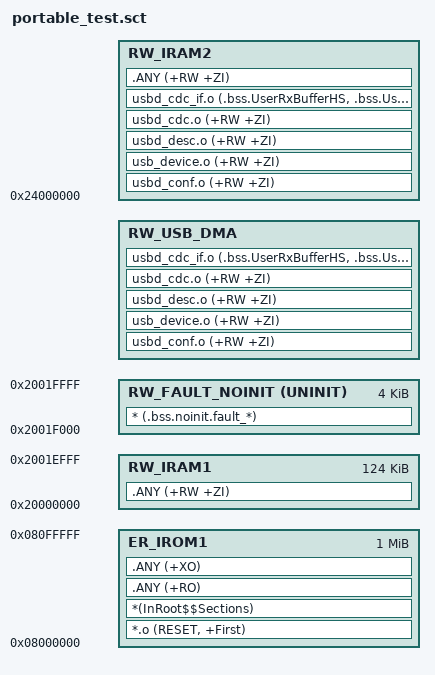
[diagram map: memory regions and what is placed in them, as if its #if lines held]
#! armclang -E --target=arm-arm-none-eabi -mcpu=cortex-m7 -xc
#include "D:/RM/recorder233/recorder_f405/diagnostics/user_add_readme/fixtures/USB portable project/User/Log/fault_log_config.h"
#include "D:/RM/recorder233/recorder_f405/diagnostics/user_add_readme/fixtures/USB portable project/User/Support/usb_dma_memory.h"
/* 故障保留区与缓存开关无关，始终保留。 */
LR_IROM1 0x08000000 0x00100000 {
  ER_IROM1 0x08000000 0x00100000 {
    *.o (RESET, +First)
    *(InRoot$$Sections)
    .ANY (+RO)
    .ANY (+XO)
  }
  RW_IRAM1 0x20000000 0x0001F000 {
    .ANY (+RW +ZI)
  }
#if FAULT_LOG_TEST_IRAM1
  RW_FAULT_NOINIT 0x2001F000 UNINIT 0x00001000 {
#else
  RW_FAULT_NOINIT 0x2404F000 UNINIT 0x00001000 {
#endif
    * (.bss.noinit.fault_*)
  }
#if USB_DMA_PROTECTED_REQUIRED
  RW_USB_DMA USB_DMA_REGION_BASE USB_DMA_REGION_BYTES {
    usbd_conf.o (+RW +ZI)
    usb_device.o (+RW +ZI)
    usbd_desc.o (+RW +ZI)
    usbd_cdc.o (+RW +ZI)
    usbd_cdc_if.o (.bss.UserRxBufferHS, .bss.UserTxBufferHS)
  }
#endif
#if USB_DMA_PROTECTED_REQUIRED
  RW_IRAM2 0x24000000 (USB_DMA_REGION_BASE - 0x24000000) {
#elif FAULT_LOG_TEST_IRAM1
  RW_IRAM2 0x24000000 0x00050000 {
#else
  RW_IRAM2 0x24000000 0x0004F000 {
#endif
#if DMA_MEMORY_USB_DMA_ENABLED && !USB_DMA_PROTECTED_REQUIRED
    /* 关闭缓存仍须保证 DMA 数据位于 AXI SRAM，不能落入 DTCM。 */
    usbd_conf.o (+RW +ZI)
    usb_device.o (+RW +ZI)
    usbd_desc.o (+RW +ZI)
    usbd_cdc.o (+RW +ZI)
    usbd_cdc_if.o (.bss.UserRxBufferHS, .bss.UserTxBufferHS)
#endif
    .ANY (+RW +ZI)
  }
}
